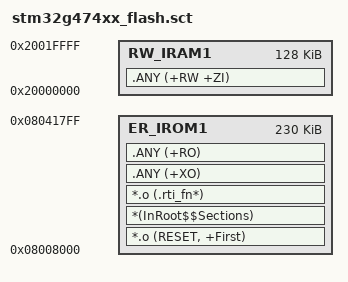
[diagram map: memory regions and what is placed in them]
LR_IROM1 0x8008000 0x00039800  {  ; load_region size_region
  ER_IROM1 0x8008000 0x00039800  {  ; load address = excetion address
   *.o (RESET, +First)
   *(InRoot$$Sections)
   *.o (.rti_fn*)
   .ANY (+XO)
   .ANY (+RO)
  }
  RW_IRAM1 0x20000000 0x00020000  {  ; load address = excetion address
   .ANY (+RW +ZI)
  }
;***region***;
;***endregion***;
}


/*-Start of  regions- Auto-generated By STM32CubeMX-*/
